# target register map
Vendor: Vango; Series: TARGET; File version: 1.0
CPU: CM0 r0p0, little endian, no MPU, no FPU, 2 interrupt priority bits
Registers are 32-bit, read-write, reset 0x0 unless marked. A register's access mark holds for its fields unless they carry their own. Offsets are from the block's base; [hi:lo] are bit positions; {n}, {i} and the like mark numbered series; 'fields as' and 'values as' point back to an identical list.

## DMA — DMA(Direct Memory Access)
Base 0x40010000
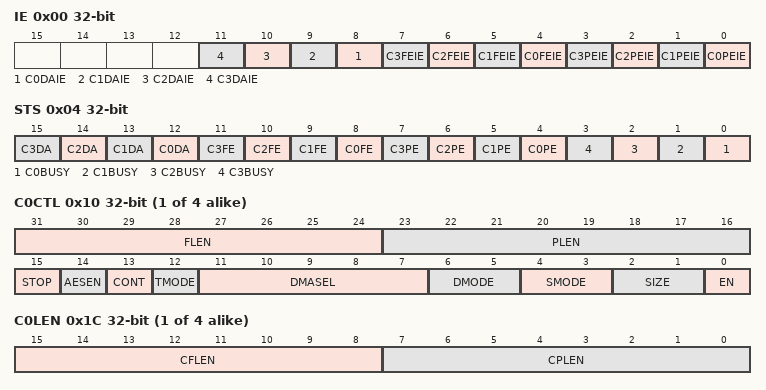
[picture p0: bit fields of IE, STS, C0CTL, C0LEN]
0x00 IE — DMA interrupt enable register.
  [n+8] C{n}DAIE (n=0..3) — Channel {n} data abort interrupt enable
  [n+4] C{n}FEIE (n=0..3) — Channel {n} frame end interrupt enable.
  [n] C{n}PEIE (n=0..3) — Channel {n} package end interrupt enable.
0x04 STS — DMA status register.
  [n+12] C{n}DA write-1-clears (n=0..3) — Channel {n} data abort interrupt flag.
  [n+8] C{n}FE write-1-clears (n=0..3) — Channel {n} frame end interrupt flag.
  [n+4] C{n}PE write-1-clears (n=0..3) — Channel {n} package end interrupt flag.
  [n] C{n}BUSY ro (n=0..3) — DMA channel {n} busy register.
{0x10+0x10*i} C{i}CTL (i=0..3) — DMA channel x control register.
  [31:24] FLEN — Frame length register actual transfer frame length is (FLEN + 1).
  [23:16] PLEN — Package length register actual transfer package length is (PLEN + 1).
  [15] STOP — Force stop DMA transfer.
  [14] AESEN — Enable AES encrypt/decrypt function of DMA channel. Only DMA channel 3 supports AES function.
  [13] CONT — Continuous mode.
  [12] TMODE — Transmit mode.
  [11:7] DMASEL — DMA request source selection.
    0=Software; 1=ADC; 2=UART0_TX; 3=UART0_RX; 4=UART1_TX; 5=UART1_RX; 6=UART2_TX; 7=UART2_RX; 8=UART3_TX; 9=UART3_RX; 10=UART4_TX; 11=UART4_RX; 12=UART5_TX; 13=UART5_RX; 14=ISO78160_TX; 15=ISO78160_RX; 16=ISO78161_TX; 17=ISO78161_RX; {v}=TIMER{v-18} (v=18..21); 22=SPI1_TX; 23=SPI1_RX; 24=UART_32K0; 25=UART_32K1; 26=CMP1; 27=CMP2; 28=SPI3_TX; 29=SPI3_RX; 30=SPI2_TX; 31=SPI2_RX
  [6:5] DMODE — Destination address mode.
    0=Fix; 1=Incremental_and_rounded_at_package_end; 2=Incremental_and_rounded_at_frame_end
  [4:3] SMODE — Source address mode.
    values as DMODE
  [2:1] SIZE — Transfer size mode.
    0=Byte; 1=Half_word; 2=Word
  [0] EN — DMA channel enable register.
{0x14+0x10*i} C{i}SRC (i=0..3) — DMA source address register.
  [31:0] SRC — Source address.
{0x18+0x10*i} C{i}DST (i=0..3) — DMA channel x destination register.
  [31:0] DST — Destination address.
{0x1C+0x10*i} C{i}LEN (i=0..3) — DMA channel x transfer length register.
  [15:8] CFLEN — Current frame transferred length.
  [7:0] CPLEN — Current package transferred length.
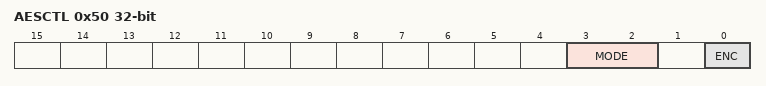
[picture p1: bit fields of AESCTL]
0x50 AESCTL — DMA AES control register.
  [3:2] MODE — AES mode selection register.
    0=AES128; 1=AES192; 2=AES256
  [0] ENC — AES encode/decode selection register.
{0x60+4i} AESKEY[{i}] (i=0..7) — DMA AES key x register. When mode is AES128, only register KEY3~KEY0 is used. When mode is AES192, only register KEY5~KEY0 is used. When mode is AES256, register KEY7~KEY0 is used.
  [31:0] KEY — AES KEY register.

## FLASH
Base 0x000FFF00
0xA8 ICEPROT — ICE protect register.
  [31:0] ICEPROT — This bit is used to indicate if the ICE protection mode is set or not.
0xAC RDPROT ro — Flash read protect status register
  [31:0] RDPORT — This register is used to indicate if the specific region has been protected from read operation during ICE mode (MODE is 0).
0xB0 WRPROT — Flash write protect control register
  [31:0] WRPORT — This register is used to protect specific region of flash from erase or program operation.
0xBC STS ro — Flash programming status register.
  [4:0] STS — Flash controller status register.
0xCC INTSTS — FLASH Checksum interrupt status
  [0] CSERR write-1-clears — Checksum error status bit.
0xD0 CSSADDR — FLASH Checksum start address
  [18:0] CSSADDR — Checksum start address register.
0xD4 CSEADDR reset 0x7FFFC — FLASH Checksum end address.
  [18:0] CSEADDR — Checksum end address register.
0xD8 CSVALUE ro — FLASH Checksum value register
  [31:0] CSVALUE — Checksum latched value register.
0xDC CSCVALUE — FLASH Checksum compare value register.
  [31:0] CSCVALUE — Checksum compare value register.
0xE0 PASS — FLASH password register
  [0] UNLOCK ro — The UNLOCK bit is used to indicate the flash program has been unlocked or not.
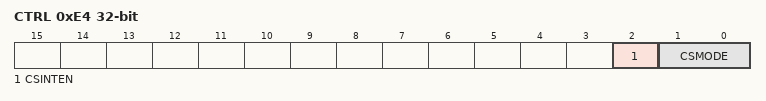
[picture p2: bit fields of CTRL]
0xE4 CTRL — FLASH control register.
  [2] CSINTEN — This register is used to control the interrupt enable of checksum error.
  [1:0] CSMODE — This register is used to control the checksum mode.
    0=Disable; 1=AlwaysOn; 2=Timer2_Overflow; 3=Rising_edge_of_RTC_second_pulse
0xE8 PGADDR — FLASH program address register.
  [17:0] PGADDR — This register is used to control the program address before doing program.
0xEC PGDATA — FLASH program word data register.
  [31:0] PGDATA — This register is used to control the program data.
0xF4 SERASE — FLASH sector erase control register.
  [0] SERASE ro — This bit is used to indicate if the sector erase is ongoing or not.
0xF8 CERASE — FLASH chip erase control register.
  [0] CERASE ro — This bit is used to indicate if the chip erase is ongoing or not.
0xFC DSTB — FLASH deep standby control register.
  [0] DSTB ro — This bit is used to indicate if the flash IP is entering deep standby.
